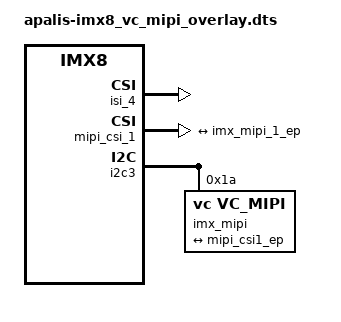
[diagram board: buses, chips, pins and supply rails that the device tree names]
// VC MIPI CSI-2 Camera Module
// Based on /device-tree-overlays/overlays/apalis-imx8_ov5640_overlay.dts

/dts-v1/;
/plugin/;

#include <dt-bindings/clock/imx8-clock.h>
#include <dt-bindings/gpio/gpio.h>

#define VC_MIPI_LANES   2
#if VC_MIPI_LANES == 1
    #define DATA_LANES <1>
    #define NUM_LANES "1" 
#endif
#if VC_MIPI_LANES == 2
    #define DATA_LANES <1 2>
    #define NUM_LANES "2" 
#endif
#if VC_MIPI_LANES == 4
    #define DATA_LANES <1 2 3 4>
    #define NUM_LANES "4" 
#endif

/ {
	compatible = "toradex,apalis-imx8";
};

&isi_4 { 
	status = "okay";

	cap_device {
		status = "okay";
	};
};

&mipi_csi_1 { 
	#address-cells = <1>;
	#size-cells = <0>;
	// /delete-property/virtual-channel;
	status = "okay";

	/* Camera 1 MIPI CSI-2 (CSIS0) */
	port@1 {
		reg = <1>;

		mipi_csi1_ep: endpoint {
			data-lanes = DATA_LANES;
			remote-endpoint = <&imx_mipi_1_ep>;
		};
	};
};

&i2c3 { 
	#address-cells = <1>;
	#size-cells = <0>;
	status = "okay";

	imx_mipi@1a {
		compatible 	= "vc,vc_mipi";
		reg 		= <0x1a>;
		status 		= "okay";

		num_lanes 	= NUM_LANES;
		// Trigger Modes:
		// 0: DISABLE     
		// 1: EXTERNAL    2: PULSEWIDTH  
		// 3: SELF        4: SINGLE      5: SYNC
		// 6: STREAM EDGE 7: STREAM LEVEL
		trigger_mode 	= "1";
		flash_mode 	= "1";
		frame_rate      = "10";

		port {
			imx_mipi_1_ep: endpoint {
				clocks-lanes = <0>;
				remote-endpoint = <&mipi_csi1_ep>;
			};
		};
    	};
};
